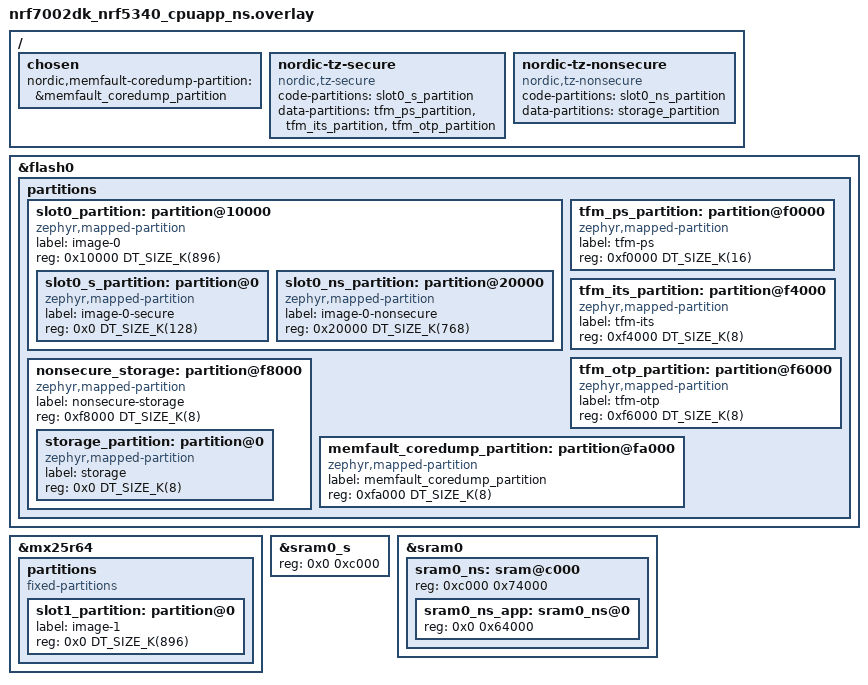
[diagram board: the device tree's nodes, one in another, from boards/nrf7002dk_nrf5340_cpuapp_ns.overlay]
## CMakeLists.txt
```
#
# Copyright (c) 2022 Nordic Semiconductor ASA
#
# SPDX-License-Identifier: LicenseRef-Nordic-5-Clause
#

cmake_minimum_required(VERSION 3.20.0)

find_package(Zephyr REQUIRED HINTS $ENV{ZEPHYR_BASE})
project(dryspool)

# Exactly one of mqtt.conf or coap.conf must be selected
if(NOT CONFIG_NRF_CLOUD_MQTT AND NOT CONFIG_NRF_CLOUD_COAP)
  message(FATAL_ERROR
    "No nRF Cloud transport selected. Build with "
    "-DEXTRA_CONF_FILE=\"mqtt.conf\" or -DEXTRA_CONF_FILE=\"coap.conf\" (or a file list "
    "including one of them).")
elseif(CONFIG_NRF_CLOUD_MQTT AND CONFIG_NRF_CLOUD_COAP)
  message(FATAL_ERROR
    "Both nRF Cloud transports are enabled. Build with only one of "
    "-DEXTRA_CONF_FILE=\"mqtt.conf\" or -DEXTRA_CONF_FILE=\"coap.conf\".")
endif()

# Include certs files if enabled.
zephyr_include_directories_ifdef(CONFIG_NRF_CLOUD_PROVISION_CERTIFICATES certs)

# NORDIC SDK APP START
target_sources(app PRIVATE src/main.c)
target_sources(app PRIVATE src/application.c)
target_sources(app PRIVATE src/cloud_connection.c)
target_sources(app PRIVATE src/message_queue.c)
target_sources(app PRIVATE src/dryspool_sensors.c)
target_sources(app PRIVATE src/led_control.c)
target_sources(app PRIVATE src/sample_reboot.c)
target_sources(app PRIVATE src/shadow_config.c)

if(CONFIG_COAP_SHADOW)
  target_sources(app PRIVATE src/shadow_support_coap.c)
endif()

if(CONFIG_SAMPLE_MEMFAULT_FOTA)
  target_sources(app PRIVATE src/memfault_fota_support.c)
endif()

if(CONFIG_MEMFAULT_METRICS_BATTERY_ENABLE)
  target_sources(app PRIVATE src/dryspool_power.c)
endif()

if(CONFIG_SAMPLE_MEMFAULT_BUTTONS)
  target_sources(app PRIVATE src/memfault_buttons.c)
endif()

# NORDIC SDK APP END

zephyr_include_directories(src)
zephyr_include_directories(config)
```

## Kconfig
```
#
# Copyright (c) 2022 Nordic Semiconductor ASA
#
# SPDX-License-Identifier: LicenseRef-Nordic-5-Clause
#

menu "DrySpool firmware settings"

config APP_VERSION
	string "DrySpool application version"
	default "0.1.6"

config CLOUD_CONNECTION_RETRY_TIMEOUT_SECONDS
	int "Cloud connection retry timeout (seconds)"
	default 30
	help
	  If connecting to nRF Cloud takes longer than this timeout, it will be
	  reattempted.

config CLOUD_READY_TIMEOUT_SECONDS
	int "Cloud readiness timeout (seconds)"
	default 600
	help
	  If the connection to nRF Cloud does not become ready within this
	  timeout, the sample will reset its connection and try again.

config DATE_TIME_ESTABLISHMENT_TIMEOUT_SECONDS
	int "Date and time establishment timeout (seconds)"
	default 300
	help
	  The sample will wait this many seconds for the device to determine the
	  current date and time before giving up and moving on.

config APPLICATION_THREAD_STACK_SIZE
	int "Application Thread Stack Size (bytes)"
	default 2048
	help
	  Sets the stack size (in bytes) for the application thread of the
	  sample.

config CONNECTION_THREAD_STACK_SIZE
	int "Connection Thread Stack Size (bytes)"
	default 2048
	help
	  Sets the stack size (in bytes) for the connection thread of the
	  sample.

config MESSAGE_THREAD_STACK_SIZE
	int "Message Queue Thread Stack Size (bytes)"
	default 2048
	help
	  Sets the stack size (in bytes) for the message queue processing
	  thread of the sample.

config LED_THREAD_STACK_SIZE
	int "LED Thread Stack Size (bytes)"
	default 1024
	help
	  Sets the stack size (in bytes) for the LED thread.

config MAX_OUTGOING_MESSAGES
	int "Outgoing message maximum"
	default 25
	help
	  Sets the maximum number of device messages which may be enqueued
	  before further messages are dropped.
	  Increasing this value may require an increase to CONFIG_HEAP_MEM_POOL_SIZE.

config MAX_CONSECUTIVE_SEND_FAILURES
	int "Max outgoing consecutive send failures"
	default 5
	help
	  Sets the maximum number of device messages which may fail to send
	  before a connection reset and cooldown is triggered.

config CONSECUTIVE_SEND_FAILURE_COOLDOWN_SECONDS
	int "Cooldown after max consecutive send failures exceeded"
	default 10
	help
	  If a connection reset is triggered by too many failed device
	  messages, the sample will wait this long (in seconds) before trying
	  again.

config SENSOR_SAMPLE_INTERVAL_SECONDS
	int "Sensor sampling interval (seconds)"
	default 60
	help
	  Sets the time to wait between each sensor sample.

config DRYSPOOL_SIMULATED_SENSORS
	bool "Use simulated DrySpool sensor readings"
	default y
	help
	  Provides deterministic temperature, humidity, remaining-filament, and
	  dehumidifier readings until the production sensors and drivers are selected.
	  Disable this option when a real DrySpool board sensor backend is added.

choice
	prompt "LED indication"
	default LED_INDICATION_GPIO if $(dt_compat_enabled,gpio-leds)
	default LED_INDICATION_DISABLED

config LED_INDICATION_GPIO
	bool "Enable LED indication using the gpio-leds driver"
	select LED
	select LED_GPIO

config LED_INDICATION_DISABLED
	bool "Disable LED indication"

endchoice

choice
	prompt "LED indication LED type"
	depends on !LED_INDICATION_DISABLED
	default LED_INDICATOR_4LED if !LED_INDICATION_DISABLED
	default LED_INDICATOR_NONE

config LED_INDICATOR_4LED
	bool "Four binary LEDs"
	depends on !LED_INDICATION_DISABLED

config LED_INDICATOR_NONE
	bool "No indicator LEDs"
	depends on LED_INDICATION_DISABLED

endchoice

config LED_VERBOSE_INDICATION
	bool "Enables extra LED status indications"
	depends on !LED_INDICATION_DISABLED
	default y

config LED_CONTINUOUS_INDICATION
	bool "Show an idle pattern instead of turning LEDs off"
	depends on !LED_INDICATION_DISABLED
	default y

config TEST_COUNTER
	bool "Sets whether the test counter is enabled"
	help
	  When enabled, the test counter configuration setting in the shadow is ignored.

config TEST_COUNTER_MULTIPLIER
	int "The number of test counter messages sent on each update"
	default 1
	range 1 1000
	help
	  This is a way to increase the number of device messages sent by the sample.
	  It is useful for load testing.

if NRF_CLOUD_COAP

menuconfig COAP_SHADOW
	bool "Updating shadow service"
	default y
	help
	  Updates the shadow with device information. Checks for a shadow
	  delta periodically and processes it if received.

if COAP_SHADOW

config COAP_SHADOW_CHECK_RATE_SECONDS
	int "Shadow job check interval (seconds)"
	default 300
	help
	  Sets the time to wait between each request to get any change to the
	  device shadow.

config COAP_SHADOW_THREAD_STACK_SIZE
	int "CoAP Shadow Thread Stack Size (bytes)"
	default 3072
	help
	  Sets the stack size (in bytes) for the CoAP shadow thread of the
	  sample.

endif

config COAP_SEND_CONFIRMABLE
	bool "Send device messages as confirmable"
	help
	  Ensures all CoAP transfers, even for often less important messages such
	  as sensor data, are sent as confirmable messages.

config SAMPLE_MEMFAULT_FOTA
	bool "Application FOTA using Memfault Release Management"
	depends on BOOTLOADER_MCUBOOT
	depends on $(dt_nodelabel_enabled,slot1_partition)
	depends on MCUBOOT_BOOTLOADER_MODE_SWAP_USING_OFFSET || MCUBOOT_BOOTLOADER_MODE_SWAP_USING_MOVE || \
			MCUBOOT_BOOTLOADER_MODE_SWAP_SCRATCH || MCUBOOT_BOOTLOADER_MODE_RAM_LOAD_WITH_REVERT || \
			MCUBOOT_BOOTLOADER_MODE_DIRECT_XIP_WITH_REVERT
	help
	  Enables application firmware updates delivered through Memfault
	  Release Management. Requires a MCUboot mode that supports the
	  test/confirm revert mechanism, since the sample relies on
	  boot_write_img_confirmed() to mark an update as good.

config SAMPLE_MEMFAULT_BUTTONS
	bool "Trigger Memfault actions with DK buttons"
	default y
	depends on MEMFAULT
	select DK_LIBRARY
	help
	  Lets the application trigger Memfault actions on demand, instead of
	  waiting for the Memfault SDK's periodic upload timer:
	  The first button (sw0) captures a metrics heartbeat and posts all pending chunks.
	  The second button (sw1) checks for a FOTA update (requires SAMPLE_MEMFAULT_FOTA).

config SAMPLE_MEMFAULT_BUTTONS_THREAD_STACK_SIZE
	int "Memfault buttons thread stack size (bytes)"
	default 4096
	depends on SAMPLE_MEMFAULT_BUTTONS
	help
	  Sets the stack size (in bytes) for the thread that runs the
	  button-triggered Memfault actions.

endif

endmenu

if NRF_CLOUD_MQTT
module-str = MQTT nRF Cloud
endif
if NRF_CLOUD_COAP
module-str = CoAP nRF Cloud
endif
module = WIFI_NRF_CLOUD
source "$(ZEPHYR_BASE)/subsys/logging/Kconfig.template.log_config"

menu "Zephyr Kernel"
source "Kconfig.zephyr"
endmenu
```

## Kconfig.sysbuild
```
#
# Copyright (c) 2024 Nordic Semiconductor
#
# SPDX-License-Identifier: LicenseRef-Nordic-5-Clause
#

config WIFI_NRF70
	default y if BOARD_NRF7002DK_NRF5340_CPUAPP_NS

config PARTITION_MANAGER
	default n

# MCUBoot is not fully supported on nRF7120/ns yet
choice BOOTLOADER
	default BOOTLOADER_MCUBOOT
endchoice

source "share/sysbuild/Kconfig"
```

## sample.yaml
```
sample:
  name: DrySpool Wi-Fi nRF Cloud FOTA firmware
tests:
  dryspool.wifi.coap.fota:
    sysbuild: true
    build_only: true
    integration_platforms:
      - nrf7002dk/nrf5340/cpuapp/ns
    platform_allow:
      - nrf7002dk/nrf5340/cpuapp/ns
    extra_args:
      - EXTRA_CONF_FILE="coap.conf;coap-fota.conf"
    tags:
      - dryspool
      - wifi
      - fota
      - sysbuild
```

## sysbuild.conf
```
# DrySpool uses its own ECDSA-P256 root-of-trust key.
# The private key is intentionally ignored by Git and must be distributed to
# teammates through a secure out-of-band channel.
SB_CONFIG_BOOT_SIGNATURE_TYPE_ECDSA_P256=y
SB_CONFIG_BOOT_SIGNATURE_KEY_FILE="\${APPLICATION_CONFIG_DIR}/keys/dryspool-signing.pem"
```

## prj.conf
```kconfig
#
# Copyright (c) 2022 Nordic Semiconductor ASA
#
# SPDX-License-Identifier: LicenseRef-Nordic-5-Clause
#

# Log level
CONFIG_LOG_PRINTK=y
CONFIG_NET_LOG=y
# For more verbose and detailed log output, set the log level to
# CONFIG_WIFI_NRF_CLOUD_LOG_LEVEL_DBG=y instead.
CONFIG_WIFI_NRF_CLOUD_LOG_LEVEL_INF=y

# General config
CONFIG_EVENTS=y
CONFIG_PICOLIBC_IO_FLOAT=y
CONFIG_RESET_ON_FATAL_ERROR=y
CONFIG_NCS_SAMPLES_DEFAULTS=y

# Improved Logging
# CONFIG_LOG_MODE_DEFERRED allows logging from multiple threads simultaneously without creating
# splintered log entries, at the cost of needing a buffer for storing logs.
CONFIG_LOG_MODE_DEFERRED=y

# CONFIG_LOG_BUFFER_SIZE is the aforementioned buffer. A size of 4096 bytes is useful for debugging
# and prototyping, but is probably more than necessary for production-ready firmware.
CONFIG_LOG_BUFFER_SIZE=4096

# Heap and stacks
# Extended memory heap size needed for Wi-Fi operation and encoding JSON-based nRF Cloud Device Messages.
# Add 256 bytes for each additional scanning result (CONFIG_NRF_WIFI_SCAN_MAX_BSS_CNT),
# assuming sane SSID lengths.
CONFIG_HEAP_MEM_POOL_SIZE=40144
CONFIG_HEAP_MEM_POOL_IGNORE_MIN=y
CONFIG_SYSTEM_WORKQUEUE_STACK_SIZE=4096
CONFIG_MAIN_STACK_SIZE=2048

# Enable Networking and Connection Manager.
CONFIG_NETWORKING=y
CONFIG_NET_SOCKETS=y
CONFIG_NET_SOCKETS_OFFLOAD=n
CONFIG_NET_MGMT_EVENT_QUEUE_SIZE=30
CONFIG_NET_CONNECTION_MANAGER_MONITOR_STACK_SIZE=6144
CONFIG_NET_CONNECTION_MANAGER=y

CONFIG_NET_IPV4=y
CONFIG_NET_IPV6=y
CONFIG_NET_IPV6_NBR_CACHE=n
CONFIG_NET_IPV6_MLD=n

# DNS
CONFIG_DNS_RESOLVER=y
CONFIG_NET_SOCKETS_DNS_TIMEOUT=30000

# Wi-Fi drivers
CONFIG_WIFI=y


# Wi-Fi conn_mgr bindings
CONFIG_L2_WIFI_CONNECTIVITY=y

# Wi-Fi credentials (simplified Wi-Fi connection setup)
CONFIG_WIFI_CREDENTIALS=y

# Wi-Fi networking and native networking stack
# Note: WIFI_NM_WPA_SUPPLICANT requires 24kB of unused RAM in the final build.
# Memory allocations are fine-tuned with that fact in mind.
CONFIG_WIFI_NM_WPA_SUPPLICANT=y
CONFIG_NET_L2_ETHERNET=y
CONFIG_NET_NATIVE=y
CONFIG_NET_SOCKETS_SOCKOPT_TLS=y
# Allow the FOTA download (HTTPS) to run concurrently with the nRF Cloud CoAP/DTLS conn.
CONFIG_NET_SOCKETS_TLS_MAX_CONTEXTS=2
CONFIG_NET_SOCKETS_TLS_MAX_SESSION_CONTEXTS=2
CONFIG_NET_MAX_CONN=8
CONFIG_NET_MAX_CONTEXTS=8

# Shrink TLS record size and negotiate the smaller size, allowing for
# two concurrent TLS/DTLS sessions (nRF Cloud CoAP + FOTA HTTPS) to fit within the
# available mbedTLS heap (CONFIG_MBEDTLS_HEAP_SIZE).
CONFIG_MBEDTLS_SSL_IN_CONTENT_LEN=4096
CONFIG_MBEDTLS_SSL_OUT_CONTENT_LEN=4096
CONFIG_MBEDTLS_SSL_MAX_FRAGMENT_LENGTH=y

CONFIG_NET_CONTEXT_SNDTIMEO=y
CONFIG_NET_TCP=y
CONFIG_NET_DHCPV4=y

# MBEDTLS base configuration for Wi-Fi TLS/DTLS
CONFIG_MBEDTLS=y
CONFIG_MBEDTLS_ENABLE_HEAP=y
CONFIG_MBEDTLS_SSL_SERVER_NAME_INDICATION=y
CONFIG_MBEDTLS_HEAP_SIZE=65536
# PEM parsing is required for TLS credentials provisioned via the shell
CONFIG_MBEDTLS_PEM_PARSE_C=y
# Needed to parse/verify RSA-signed CA certificates (e.g. Amazon Root CA1, used by
# CONFIG_NRF_CLOUD_PROVISION_CERTIFICATES's hardcoded credentials flow).
CONFIG_MBEDTLS_CIPHERSUITE_TLS_ECDHE_RSA_WITH_AES_128_CBC_SHA256=y
CONFIG_PSA_WANT_ALG_ECDSA=y
# PBKDF2-HMAC is needed for WPA2-PSK passphrase hashing (pbkdf2_sha1)
CONFIG_PSA_WANT_ALG_PBKDF2_HMAC=y
CONFIG_PSA_WANT_ALG_PBKDF2_AES_CMAC_PRF_128=y

# Wait for credential installation to be complete before connecting to nRF Cloud
CONFIG_NRF_CLOUD_CHECK_CREDENTIALS=y

# nRF Cloud
# Transport (MQTT or CoAP) is selected explicitly via mqtt.conf or coap.conf.
CONFIG_NRF_CLOUD=y

# Use compile-time client ID for nRF Cloud
CONFIG_NRF_CLOUD_CLIENT_ID_SRC_HW_ID=y
CONFIG_HW_ID_LIBRARY=y
CONFIG_HW_ID_LIBRARY_SOURCE_DEVICE_ID=y

# Limit the scan result set to keep the Wi-Fi heap bounded.
CONFIG_NRF_WIFI_SCAN_MAX_BSS_CNT=10

# Date Time lib - Used by main application
CONFIG_DATE_TIME=y
# Enable date_time retries for Wi-Fi
# This prevents occasional DNS lookup flukes from
# rendering the device unable to connect until the next
# CONFIG_DATE_TIME_UPDATE_INTERVAL_SECONDS elapses (default 4 hours)
CONFIG_DATE_TIME_RETRY_COUNT=5
# Use a really short retry interval for demo purposes
# 60 seconds to 15 minutes is probably more appropriate for real-world applications
CONFIG_DATE_TIME_RETRY_INTERVAL_SECONDS=20

# Settings are used by nRF Cloud (MQTT persistent session, FOTA) and for Wi-Fi credentials
# on TFM-less builds. The storage backend (ZMS or NVS) is selected in each board's .conf file.
CONFIG_SETTINGS=y

# Flash
CONFIG_FLASH=y
CONFIG_FLASH_PAGE_LAYOUT=y
CONFIG_FLASH_MAP=y

# Run the application as the non-secure image behind TF-M. Keep these settings
# explicit so pristine sysbuilds include Protected Storage and the crypto
# support used by the nRF Cloud credentials.
CONFIG_BUILD_WITH_TFM=y
CONFIG_TRUSTED_EXECUTION_NONSECURE=y
CONFIG_TFM_PARTITION_PROTECTED_STORAGE=y
CONFIG_TFM_PROFILE_TYPE_NOT_SET=y
CONFIG_TFM_CRYPTO_ASYM_SIGN_MODULE_ENABLED=y

# Credential management shells
CONFIG_SHELL=y
CONFIG_NET_L2_WIFI_SHELL=y
CONFIG_WIFI_CREDENTIALS_SHELL=y
CONFIG_TLS_CREDENTIALS_SHELL=y
# "net iface" shows MAC + IP; "net ping" useful for connectivity checks
CONFIG_NET_SHELL=y
CONFIG_DEVMEM_SHELL=n
# Persist TLS credentials across reboots.
CONFIG_TLS_CREDENTIALS_BACKEND_PROTECTED_STORAGE=y
# Memfault installs two root CAs and nRF Cloud needs a CA, client certificate,
# and private key. The Zephyr default of four entries cannot hold all five.
CONFIG_TLS_MAX_CREDENTIALS_NUMBER=8
# Increased stack size needed for wifi_cred auto_connect command
CONFIG_SHELL_STACK_SIZE=6144
# nRFCloud credentials can exceed 1024 bytes
CONFIG_TLS_CREDENTIALS_SHELL_CRED_BUF_SIZE=3072
# Needed by the TLS credentials shell
CONFIG_BASE64=y

# Network
CONFIG_POSIX_API=y

# Miscellaneous resource allocation tweaks needed to support Wi-Fi
CONFIG_MESSAGE_THREAD_STACK_SIZE=8192
CONFIG_CONNECTION_THREAD_STACK_SIZE=6144
CONFIG_DATE_TIME_THREAD_STACK_SIZE=2048
CONFIG_NET_TX_STACK_SIZE=1024
CONFIG_NET_RX_STACK_SIZE=2048
CONFIG_WIFI_NM_WPA_SUPPLICANT_THREAD_STACK_SIZE=6144
CONFIG_ZVFS_POLL_MAX=8

## Memory allocation
CONFIG_NRF_WIFI_CTRL_HEAP_SIZE=20000
CONFIG_NRF_WIFI_DATA_HEAP_SIZE=92856

## Thread stack sizes
CONFIG_APPLICATION_THREAD_STACK_SIZE=2048
CONFIG_NET_MGMT_EVENT_STACK_SIZE=8192

# NCS 3.4.0 does not expose the later on-device nRF Cloud credential-keygen
# options. Provision cloud credentials with the documented nRF Cloud flow.
```

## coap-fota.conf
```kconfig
#
# Copyright (c) 2026 Nordic Semiconductor ASA
#
# SPDX-License-Identifier: LicenseRef-Nordic-5-Clause
#

# We keep FOTA support in a separate file because not all targets
# are able to support it yet (nRF7120/ns). Can be merged into
# coap.conf once things are in shape.

# Set sample-local flag
CONFIG_SAMPLE_MEMFAULT_FOTA=y

# Enable FOTA
CONFIG_FOTA_DOWNLOAD=y
CONFIG_FOTA_DOWNLOAD_PROGRESS_EVT=y
CONFIG_DFU_TARGET=y
CONFIG_DOWNLOADER=y
CONFIG_IMG_MANAGER=y
CONFIG_STREAM_FLASH=y
CONFIG_IMG_ERASE_PROGRESSIVELY=y
CONFIG_REBOOT=y
# Custom callback to gracefully disconnect from nRF Cloud before reboot
CONFIG_MEMFAULT_FOTA_DOWNLOAD_CALLBACK_CUSTOM=y
# Let Memfault SDK poll for FOTA updates
CONFIG_MEMFAULT_PERIODIC_FOTA_CHECK=y

# NCS 3.4.0 caps the nRF Cloud CoAP path at 128. Memfault release checks and
# payload downloads use HTTPS in this backport, so longer CoAP paths are not needed.
CONFIG_COAP_CLIENT_MAX_PATH_LENGTH=128
CONFIG_DOWNLOADER_MAX_FILENAME_SIZE=400
CONFIG_DOWNLOADER_STACK_SIZE=8192
```

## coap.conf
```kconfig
#
# Copyright (c) 2024 Nordic Semiconductor ASA
#
# SPDX-License-Identifier: LicenseRef-Nordic-5-Clause
#

# Configure MBEDTLS for CoAP/DTLS
CONFIG_MQTT_LIB_TLS=n
CONFIG_MBEDTLS_DTLS=y
CONFIG_MBEDTLS_SSL_SRV_C=y
CONFIG_MBEDTLS_SSL_COOKIE_C=y
# Ciphersuite for CoAP
CONFIG_MBEDTLS_CIPHERSUITE_TLS_ECDHE_ECDSA_WITH_AES_128_GCM_SHA256=y
CONFIG_MBEDTLS_SSL_DTLS_HELLO_VERIFY=y
CONFIG_MBEDTLS_SSL_DTLS_CONNECTION_ID=y
CONFIG_NET_SOCKETS_ENABLE_DTLS=y

# nRF Cloud: CoAP
CONFIG_NRF_CLOUD_COAP=y
CONFIG_NRF_CLOUD_JWT_SOURCE_CUSTOM=y
CONFIG_NRF_CLOUD_COAP_MAX_USER_OPTIONS=0
CONFIG_COAP_CLIENT_MAX_EXTRA_OPTIONS=3
# Memfault requires longer CoAP options than the default
CONFIG_COAP_EXTENDED_OPTIONS_LEN_VALUE=192

# Memfault device management. NCS 3.4.0's bundled Memfault 1.40 CoAP port
# incorrectly pulls in an nRF91-only modem header on nRF7002. Use Memfault's
# supported HTTPS transport for diagnostics and release checks while keeping
# nRF Cloud CoAP for DrySpool telemetry.
CONFIG_MEMFAULT=y
CONFIG_MEMFAULT_HTTP_ENABLE=y
CONFIG_MEMFAULT_PERIODIC_UPLOAD=y
# Let the application enable upload when ready
CONFIG_MEMFAULT_PERIODIC_UPLOAD_ENABLED_DEFAULT=n
CONFIG_MEMFAULT_SHELL=y
# 3.11: heartbeat + automatic upload every 5 min (default is 1 hour) so metric
# charts fill up and OTA checks happen quickly during the demo.
CONFIG_MEMFAULT_METRICS_HEARTBEAT_INTERVAL_SECS=300
CONFIG_MEMFAULT_PERIODIC_UPLOAD_INTERVAL_SECS=300
# 3.11 metric 4.1: power status via Memfault battery metrics (see src/dryspool_power.c)
CONFIG_MEMFAULT_METRICS_BATTERY_ENABLE=y
# Memfault 1.40 declares Zephyr 4.4's system heap with an obsolete type when
# this optional metric is enabled. Keep allocation tracking/coredumps, but
# disable only the incompatible aggregate memory-usage metric.
CONFIG_MEMFAULT_METRICS_MEMORY_USAGE=n
CONFIG_MEMFAULT_NCS_FW_VERSION_STATIC=y
CONFIG_MEMFAULT_NCS_FW_TYPE="dryspool-app"
CONFIG_MEMFAULT_NCS_HW_VERSION="nrf7002dk-rev1"
CONFIG_MEMFAULT_NCS_PROJECT_KEY=""
CONFIG_MEMFAULT_ROOT_CERT_STORAGE_TLS_CREDENTIAL_STORAGE=y
CONFIG_MEMFAULT_NCS_PROVISION_CERTIFICATES=y
# Dedicated workqueue for Memfault uploads
CONFIG_MEMFAULT_PERIODIC_UPLOAD_USE_DEDICATED_WORKQUEUE=y
# Clean fault logs
CONFIG_MPU_STACK_GUARD=y
CONFIG_MEMFAULT_FAULT_HANDLER_RETURN=y

# CoAP Client
CONFIG_COAP_CLIENT_BLOCK_SIZE=1024
CONFIG_COAP_CLIENT_THREAD_PRIORITY=0

# Stack sizes
CONFIG_COAP_CLIENT_STACK_SIZE=8192
CONFIG_COAP_SHADOW_THREAD_STACK_SIZE=8192
```

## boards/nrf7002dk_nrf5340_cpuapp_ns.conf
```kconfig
#
# Copyright (c) 2026 Nordic Semiconductor ASA
#
# SPDX-License-Identifier: LicenseRef-Nordic-5-Clause
#

# Note: even when using Protected Storage, credentials are still retrieved into insecure
# memory when in use.
CONFIG_TFM_PARTITION_PROTECTED_STORAGE=y
## TF-M: keep IPC mode (default) for the MQTT build. Enable MM-IOVEC to save RAM.
CONFIG_TFM_PSA_FRAMEWORK_HAS_MM_IOVEC=y

CONFIG_TFM_CRYPTO_ASYM_SIGN_MODULE_ENABLED=y

# Use NVS for settings
CONFIG_NVS=y

# Enable LTO to save flash memory (required for CoAP overlay which would otherwise overflow)
CONFIG_LTO=y
CONFIG_ISR_TABLES_LOCAL_DECLARATION=y

#NRF70 specific configuration
CONFIG_WIFI_NRF70=y
CONFIG_WIFI_NRF70_SKIP_LOCAL_ADMIN_MAC=y

# Keep crash data in a dedicated internal-flash partition. A RAM-backed dump
# large enough for this application would exceed the nRF5340's available RAM.
CONFIG_MEMFAULT_NCS_INTERNAL_FLASH_BACKED_COREDUMP=y
CONFIG_MBEDTLS_HEAP_SIZE=49152

# Cut flash. Needed in order to fit into application image slots
CONFIG_NET_SHELL=n

# Not enough RAM for the Memfault buttons thread
CONFIG_SAMPLE_MEMFAULT_BUTTONS=n
```

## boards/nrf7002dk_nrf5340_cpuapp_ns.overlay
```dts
/*
 * Copyright (c) 2026 Nordic Semiconductor ASA
 *
 * SPDX-License-Identifier: LicenseRef-Nordic-5-Clause
 */

/* NCS 3.4 cpuapp/ns target: dual-slot MCUboot layout with external slot1. */

/delete-node/ &slot0_partition;
/delete-node/ &slot1_partition;
/delete-node/ &storage_partition;
/delete-node/ &sram0_ns;

/* Shared slot0/slot1 addresses and sizes */

&flash0 {
	partitions {
		slot0_partition: partition@10000 {
			compatible = "zephyr,mapped-partition";
			label = "image-0";
			reg = <0x10000 DT_SIZE_K(896)>;
		};
	};
};

&mx25r64 {
	partitions {
		compatible = "fixed-partitions";
		#address-cells = <1>;
		#size-cells = <1>;

		slot1_partition: partition@0 {
			label = "image-1";
			reg = <0x0 DT_SIZE_K(896)>;
		};
	};
};

&slot0_partition {
	ranges = <0x0 0x10000 DT_SIZE_K(896)>;
	#address-cells = <1>;
	#size-cells = <1>;

	slot0_s_partition: partition@0 {
		compatible = "zephyr,mapped-partition";
		label = "image-0-secure";
		reg = <0x0 DT_SIZE_K(128)>;
	};

	slot0_ns_partition: partition@20000 {
		compatible = "zephyr,mapped-partition";
		label = "image-0-nonsecure";
		reg = <0x20000 DT_SIZE_K(768)>;
	};
};

&flash0 {
	partitions {
		/*
		 * 0x10000 (boot) + 896K (slot0) = 0xf0000.
		 *
		 * nRF5340 flash security attribution has 32 KiB granularity. Keep all
		 * TF-M storage in the secure 0xf0000-0xf7fff region and all Zephyr
		 * storage in the non-secure 0xf8000-0xfffff region. Mixing secure and
		 * non-secure partitions inside either region causes TF-M Protected
		 * Storage to fault after credentials have been persisted.
		 */
		tfm_ps_partition: partition@f0000 {
			compatible = "zephyr,mapped-partition";
			label = "tfm-ps";
			reg = <0xf0000 DT_SIZE_K(16)>;
		};

		tfm_its_partition: partition@f4000 {
			compatible = "zephyr,mapped-partition";
			label = "tfm-its";
			reg = <0xf4000 DT_SIZE_K(8)>;
		};

		tfm_otp_partition: partition@f6000 {
			compatible = "zephyr,mapped-partition";
			label = "tfm-otp";
			reg = <0xf6000 DT_SIZE_K(8)>;
		};

		nonsecure_storage: partition@f8000 {
			compatible = "zephyr,mapped-partition";
			label = "nonsecure-storage";
			reg = <0xf8000 DT_SIZE_K(8)>;
			ranges = <0x0 0xf8000 DT_SIZE_K(8)>;
			#address-cells = <1>;
			#size-cells = <1>;

			storage_partition: partition@0 {
				compatible = "zephyr,mapped-partition";
				label = "storage";
				reg = <0x0 DT_SIZE_K(8)>;
			};
		};

		memfault_coredump_partition: partition@fa000 {
			compatible = "zephyr,mapped-partition";
			label = "memfault_coredump_partition";
			reg = <0xfa000 DT_SIZE_K(8)>;
		};
	};
};

/*
 * TrustZone SRAM split from devicetree (region_defs.h for TF-M). The secure image uses
 * 48 KiB (0xc000) at the base of cpuapp SRAM (&sram0_s); NS RAM begins at 0x20000000 + 0xc000.
 * &sram0_ns spans 0x74000 bytes; &sram0_ns_app is 0x64000 because the top 0x10000 (64 KiB)
 * within that NS window is sram0_shared for application/network-core IPC
 * (nrf5340_shared_sram_partition.dtsi), i.e. 0x64000 + 0x10000 == 0x74000.
 */
&sram0_s {
	reg = <0x0 0xc000>;
};

&sram0 {
	sram0_ns: sram@c000 {
		#address-cells = <1>;
		#size-cells = <1>;
		reg = <0xc000 0x74000>;
		ranges = <0x0 0xc000 0x74000>;

		sram0_ns_app: sram0_ns@0 {
			reg = <0x0 0x64000>;
		};
	};
};

/ {
	chosen {
		nordic,memfault-coredump-partition = &memfault_coredump_partition;
	};

	/delete-node/ nordic-tz-secure;
	/delete-node/ nordic-tz-nonsecure;

	nordic-tz-secure {
		compatible = "nordic,tz-secure";
		code-partitions = <&slot0_s_partition>;
		data-partitions = <&tfm_ps_partition>,
				  <&tfm_its_partition>,
				  <&tfm_otp_partition>;
	};

	nordic-tz-nonsecure {
		compatible = "nordic,tz-nonsecure";
		code-partitions = <&slot0_ns_partition>;
		data-partitions = <&storage_partition>;
	};
};
```

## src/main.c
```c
/* Copyright (c) 2023 Nordic Semiconductor ASA
 *
 * SPDX-License-Identifier: LicenseRef-Nordic-5-Clause
 */

#include <zephyr/kernel.h>
#include <stdio.h>
#include <zephyr/logging/log.h>
#include "application.h"
#include "cloud_connection.h"
#include "message_queue.h"
#include "led_control.h"
#if defined(CONFIG_NRF_CLOUD_COAP)
#include "shadow_support_coap.h"
#endif
#if defined(CONFIG_SAMPLE_MEMFAULT_BUTTONS)
#include "memfault_buttons.h"
#endif

LOG_MODULE_REGISTER(main, CONFIG_WIFI_NRF_CLOUD_LOG_LEVEL);

/* Here, we start the various threads that our application will run in */

#ifndef CONFIG_LED_INDICATION_DISABLED
/* Define, and automatically start the LED animation thread. See led_control.c */
K_THREAD_DEFINE(led_thread, CONFIG_LED_THREAD_STACK_SIZE, led_animation_thread_fn,
		NULL, NULL, NULL, 0, 0, 0);
#endif

/* Define, and automatically start the main application thread. See application.c */
K_THREAD_DEFINE(app_thread, CONFIG_APPLICATION_THREAD_STACK_SIZE, main_application_thread_fn,
		NULL, NULL, NULL, 0, 0, 0);

/* Define, and automatically start the message queue thread. See message_queue.c */
K_THREAD_DEFINE(msg_thread, CONFIG_MESSAGE_THREAD_STACK_SIZE, message_queue_thread_fn,
		NULL, NULL, NULL, 0, 0, 0);

/* Define, and automatically start the cloud connection thread. See cloud_connection.c */
K_THREAD_DEFINE(con_thread, CONFIG_CONNECTION_THREAD_STACK_SIZE, cloud_connection_thread_fn,
		NULL, NULL, NULL, 0, 0, 0);

#if defined(CONFIG_NRF_CLOUD_COAP)

#if defined(CONFIG_COAP_SHADOW)
/* Define, and automatically start the CoAP shadow check thread. See shadow_support_coap.c */
K_THREAD_DEFINE(coap_shadow, CONFIG_COAP_SHADOW_THREAD_STACK_SIZE, coap_shadow_thread_fn,
		NULL, NULL, NULL, 0, 0, 0);
#endif
#endif /* CONFIG_NRF_CLOUD_COAP */

#if defined(CONFIG_SAMPLE_MEMFAULT_BUTTONS)
/* Define, and automatically start the Memfault buttons thread. See memfault_buttons.c */
K_THREAD_DEFINE(mflt_buttons, CONFIG_SAMPLE_MEMFAULT_BUTTONS_THREAD_STACK_SIZE,
		memfault_buttons_thread_fn, NULL, NULL, NULL, 0, 0, 0);
#endif

/* main() is called from the main thread, which defaults to priority zero,
 * but for illustrative purposes we don't use it. main_application() could be called directly
 * from this function, rather than given its own dedicated thread.
 */
int main(void)
{
	const char *protocol;

	if (IS_ENABLED(CONFIG_NRF_CLOUD_MQTT)) {
		protocol = "MQTT";
	} else if (IS_ENABLED(CONFIG_NRF_CLOUD_COAP)) {
		protocol = "CoAP";
	}

	LOG_INF("DrySpool firmware started, version: %s, cloud protocol: %s",
		CONFIG_APP_VERSION, protocol);

#if defined(CONFIG_MEMFAULT_NCS_FW_VERSION_STATIC)
	LOG_INF("Memfault software_version: %s", CONFIG_MEMFAULT_NCS_FW_VERSION);
#endif

	return 0;
}
```

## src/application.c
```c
/*
 * DrySpool application telemetry.
 *
 * Based on Nordic Semiconductor's Wi-Fi nRF Cloud sample.
 * SPDX-License-Identifier: LicenseRef-Nordic-5-Clause
 */

#include <zephyr/kernel.h>
#include <zephyr/logging/log.h>
#include <helpers/nrfx_reset_reason.h>
#include <date_time.h>
#include <net/nrf_cloud_codec.h>
#include <memfault/metrics/metrics.h>

#include "application.h"
#include "cloud_connection.h"
#include "dryspool_sensors.h"
#include "message_queue.h"
#if defined(CONFIG_SAMPLE_MEMFAULT_FOTA)
#include "memfault_fota_support.h"
#endif

LOG_MODULE_REGISTER(application, CONFIG_WIFI_NRF_CLOUD_LOG_LEVEL);

static K_TIMER_DEFINE(sensor_sample_timer, NULL, NULL);
static bool test_counter_enabled;

static int send_numeric_sample(const char *const app_id, double value)
{
	int ret;
	MSG_OBJ_DEFINE(msg_obj);

	ret = nrf_cloud_obj_msg_ts_init(&msg_obj, app_id,
					NRF_CLOUD_JSON_MSG_TYPE_VAL_DATA);
	if (ret) {
		return ret;
	}

	ret = nrf_cloud_obj_num_add(&msg_obj, NRF_CLOUD_JSON_DATA_KEY, value, false);
	if (ret) {
		nrf_cloud_obj_free(&msg_obj);
		return ret;
	}

	return send_device_message(&msg_obj);
}

static void send_dryspool_sample(const struct dryspool_reading *reading)
{
	LOG_INF("DrySpool: %.1f C, %.1f %%RH, %.1f g, dehumidifier %s",
		(double)reading->temperature_c, (double)reading->humidity_pct,
		(double)reading->filament_remaining_g,
		reading->dehumidifier_on ? "on" : "off");

	/* Forward critical DrySpool data to Memfault as heartbeat metrics (x10 scaled). */
	MEMFAULT_METRIC_SET_UNSIGNED(dryspool_humidity_pct,
				     (uint32_t)(reading->humidity_pct * 10.0));
	MEMFAULT_METRIC_SET_SIGNED(dryspool_temperature_c,
				   (int32_t)(reading->temperature_c * 10.0));
	MEMFAULT_METRIC_SET_UNSIGNED(dryspool_filament_g,
				     (uint32_t)reading->filament_remaining_g);

	(void)send_numeric_sample("DRYSPOOL_TEMPERATURE_C", reading->temperature_c);
	(void)send_numeric_sample("DRYSPOOL_HUMIDITY_PCT", reading->humidity_pct);
	(void)send_numeric_sample("DRYSPOOL_FILAMENT_G", reading->filament_remaining_g);
	(void)send_numeric_sample("DRYSPOOL_DEHUMIDIFIER_ON",
				 reading->dehumidifier_on ? 1.0 : 0.0);
}

static void test_counter_send(void)
{
	static int counter;

	for (int i = 0; i < CONFIG_TEST_COUNTER_MULTIPLIER; i++) {
		(void)send_numeric_sample("COUNT", counter++);
	}
}

static void print_reset_reason(void)
{
	uint32_t reset_reason = nrfx_reset_reason_get();

	nrfx_reset_reason_clear(reset_reason);
	LOG_INF("Reset reason: 0x%x", reset_reason);
}

void main_application_thread_fn(void)
{
	struct dryspool_reading reading;
	int ret;

	print_reset_reason();

	ret = dryspool_sensors_init();
	if (ret) {
		LOG_ERR("DrySpool sensor initialization failed: %d", ret);
		return;
	}

	/* Confirm a new image only after the product sensor layer passes its
	 * startup check. If startup fails or crashes first, MCUboot can revert it.
	 */
#if defined(CONFIG_SAMPLE_MEMFAULT_FOTA)
	memfault_fota_support_init();
#endif

	(void)await_cloud_ready(K_FOREVER);

	LOG_INF("Waiting for valid network time");
	if (!await_date_time_known(K_SECONDS(CONFIG_DATE_TIME_ESTABLISHMENT_TIMEOUT_SECONDS))) {
		LOG_WRN("Valid date/time unavailable; continuing");
	}

	while (true) {
		k_timer_start(&sensor_sample_timer,
			      K_SECONDS(CONFIG_SENSOR_SAMPLE_INTERVAL_SECONDS), K_FOREVER);

		ret = dryspool_sensors_read(&reading);
		if (ret) {
			LOG_ERR("DrySpool sensor read failed: %d", ret);
		} else {
			send_dryspool_sample(&reading);
		}

		if (test_counter_enable_get()) {
			test_counter_send();
		}

		k_timer_status_sync(&sensor_sample_timer);

		if (!await_cloud_ready(K_NO_WAIT) && is_device_deleted()) {
			LOG_INF("Cloud not ready; pausing telemetry");
			(void)await_cloud_ready(K_FOREVER);
			LOG_INF("Cloud ready; resuming telemetry");
		}
	}
}

void test_counter_enable_set(const bool enable)
{
	if (!IS_ENABLED(CONFIG_TEST_COUNTER)) {
		test_counter_enabled = enable;
	}
}

bool test_counter_enable_get(void)
{
	return test_counter_enabled || IS_ENABLED(CONFIG_TEST_COUNTER);
}
```

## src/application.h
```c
/* Copyright (c) 2023 Nordic Semiconductor ASA
 *
 * SPDX-License-Identifier: LicenseRef-Nordic-5-Clause
 */

#ifndef _APPLICATION_H_
#define _APPLICATION_H_

#if defined(CONFIG_NRF_CLOUD_MQTT)
#define MSG_OBJ_DEFINE(_obj_name) \
	NRF_CLOUD_OBJ_JSON_DEFINE(_obj_name);
#elif defined(CONFIG_NRF_CLOUD_COAP)
#define MSG_OBJ_DEFINE(_obj_name) \
	NRF_CLOUD_OBJ_COAP_CBOR_DEFINE(_obj_name);
#endif

/**
 * @brief Initialize DrySpool, wait for cloud readiness, then periodically
 * sample product state and send it to nRF Cloud.
 */
void main_application_thread_fn(void);

void test_counter_enable_set(const bool enable);
bool test_counter_enable_get(void);

#endif /* _APPLICATION_H_ */
```

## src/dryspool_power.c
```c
/*
 * DrySpool power status for Memfault (requirement 3.11 - metric 4.1).
 *
 * The nRF7002 DK has no battery: it is always powered over USB. Memfault's
 * built-in battery metrics (battery_soc_pct, battery_discharge_duration_ms,
 * battery_soc_pct_drop) call this function every heartbeat, so we report
 * "100 % and not discharging" = USB/mains powered.
 *
 * PLACEHOLDER: when the DrySpool PCB gets a battery + fuel gauge, read the
 * real state of charge here instead of the constant below.
 */
#include <stdbool.h>
#include <memfault/metrics/platform/battery.h>

int memfault_platform_get_stateofcharge(sMfltPlatformBatterySoc *soc)
{
	/* 100 % in Memfault's scaled units (CONFIG_MEMFAULT_METRICS_BATTERY_SOC_PCT_SCALE_VALUE) */
	soc->soc = 100 * CONFIG_MEMFAULT_METRICS_BATTERY_SOC_PCT_SCALE_VALUE;
	soc->discharging = false; /* USB powered -> never discharging */
	return 0;
}
```

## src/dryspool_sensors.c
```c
/* SPDX-License-Identifier: LicenseRef-Nordic-5-Clause */

#include <errno.h>
#include <stddef.h>
#include <zephyr/sys/util.h>

#include "dryspool_sensors.h"

int dryspool_sensors_init(void)
{
	/* Replace this with device_is_ready() checks when the sensor and load-cell
	 * choices are finalized. Keeping this boundary stable lets those drivers be
	 * developed and tested without changing the cloud or FOTA layers.
	 */
	return 0;
}

int dryspool_sensors_read(struct dryspool_reading *reading)
{
#if defined(CONFIG_DRYSPOOL_SIMULATED_SENSORS)
	static unsigned int sample_number;

	if (reading == NULL) {
		return -EINVAL;
	}

	/* Deterministic prototype data makes the wireless demo observable before
	 * the final sensors are selected. It is not presented as real measurement.
	 */
	reading->temperature_c = 23.0 + (sample_number % 5) * 0.1;
	reading->humidity_pct = 42.0 + (sample_number % 7) * 0.2;
	reading->filament_remaining_g = 750.0 - (sample_number % 100) * 0.5;
	reading->dehumidifier_on = reading->humidity_pct > 43.0;
	sample_number++;
	return 0;
#else
	ARG_UNUSED(reading);
	return -ENOTSUP;
#endif
}
```

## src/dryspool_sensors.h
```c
/* SPDX-License-Identifier: LicenseRef-Nordic-5-Clause */

#ifndef DRYSPOOL_SENSORS_H_
#define DRYSPOOL_SENSORS_H_

#include <stdbool.h>

struct dryspool_reading {
	double temperature_c;
	double humidity_pct;
	double filament_remaining_g;
	bool dehumidifier_on;
};

int dryspool_sensors_init(void);
int dryspool_sensors_read(struct dryspool_reading *reading);

#endif /* DRYSPOOL_SENSORS_H_ */
```
